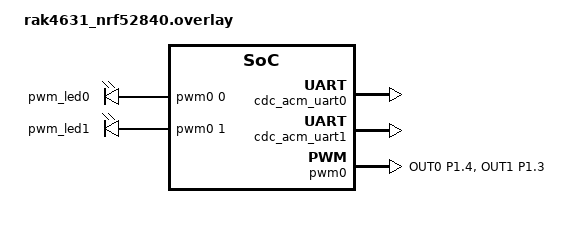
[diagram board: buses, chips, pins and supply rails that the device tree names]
/ {
	chosen {
		zephyr,console = &cdc_acm_uart0;
		zephyr,uart-mcumgr = &cdc_acm_uart1;
	};

	pwmleds {
		compatible = "pwm-leds";
		status = "okay";
		pwm_led0: pwm_led_0 {
			pwms = <&pwm0 0 PWM_MSEC(20) PWM_POLARITY_INVERTED>;
		};
		pwm_led1: pwm_led_1 {
			pwms = <&pwm0 1 PWM_MSEC(20) PWM_POLARITY_INVERTED>;
		};
	};

	leds {
		status = "disabled";
	};
};

&zephyr_udc0 {
	cdc_acm_uart0: cdc_acm_uart0 {
		compatible = "zephyr,cdc-acm-uart";
	};
	cdc_acm_uart1: cdc_acm_uart1 {
		compatible = "zephyr,cdc-acm-uart";
	};
};

&pwm0 {
	status = "okay";
	pinctrl-0 = <&pwm0_default>;
	pinctrl-1 = <&pwm0_sleep>;
	pinctrl-names = "default", "sleep";
};

&pinctrl {
	pwm0_default: pwm0_default {
		group1 {
			psels = <NRF_PSEL(PWM_OUT0, 1, 4)>;
		};
		group2 {
			psels = <NRF_PSEL(PWM_OUT1, 1, 3)>;
		};
	};

	pwm0_sleep: pwm0_sleep {
		group1 {
			psels = <NRF_PSEL(PWM_OUT0, 1, 4)>;
			low-power-enable;
		};
		group2 {
			psels = <NRF_PSEL(PWM_OUT1, 1, 3)>;
			low-power-enable;
		};
	};
};
